# S32M24x register map
Vendor: NXP Semiconductors; File version: 1.5
CPU: CM4 r0p1, little endian, MPU, FPU, VTOR, 4 interrupt priority bits
Registers are 32-bit, read-write, reset 0x0 unless marked. A register's access mark holds for its fields unless they carry their own. Offsets are from the block's base; [hi:lo] are bit positions; 'fields as' and 'values as' point back to an identical list.

## HVI_AE — HVM
Base 0x00000200
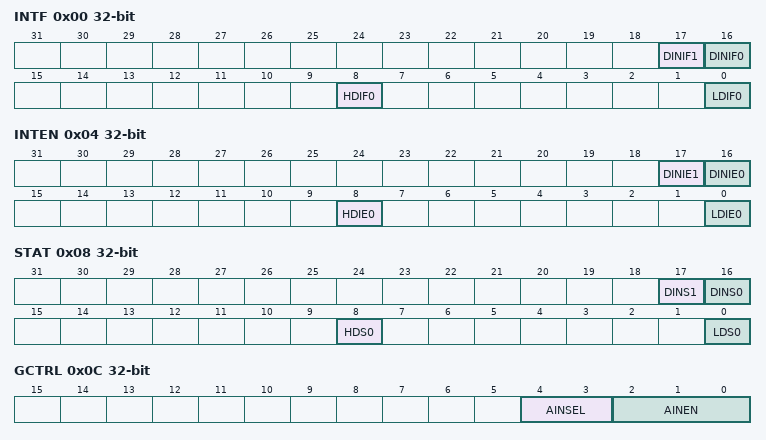
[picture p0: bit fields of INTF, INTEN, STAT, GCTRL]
0x00 INTF write-1-clears — Interrupt Flags
  [17] DINIF1 write-1-clears — Digital Input Interrupt Flag 1
    0=NO_DINIF (HVI n did not detect an event on its digital input.); 1=ACTIVE_DINIF (HVI n detected an event on its digital input.)
  [16] DINIF0 write-1-clears — Digital Input Interrupt Flag 0
    values as DINIF1
  [8] HDIF0 write-1-clears — High Detect Interrupt Flag 0
    0=NO_HVDBATS (VM n did not detect a high voltage since the last clearing of the bit.); 1=ACTIVE_HVDBATS (VM n detected a high voltage since the last clearing of the bit.)
  [0] LDIF0 write-1-clears — Low Detect Interrupt Flag 0
    0=NO_LVD (VM n did not detect a low voltage since the last clearing of the bit.); 1=ACTIVE_LVD (VM n detected a low voltage since the last clearing of this bit.)
0x04 INTEN — Interrupt Enables
  [all] fields
    0=disint (Disable interrupt); 1=enint (Enable interrupt)
  [17] DINIE1 — Digital Input Interrupt Enable 1
  [16] DINIE0 — Digital Input Interrupt Enable 0
  [8] HDIE0 — High Detect Interrupt Enable 0
  [0] LDIE0 — Low Detect Interrupt Enable 0
0x08 STAT ro — Status
  [17] DINS1 — Digital Input Status 1
    0=ZERO (The digital input is in the inactive state with respect to the defined polarity.); 1=ONE (The digital input is in the active state with respect to the defined polarity.)
  [16] DINS0 — Digital Input Status 0
    values as DINS1
  [8] HDS0 — High Detect Status 0
    0=ZERO (The high voltage monitor does not detect a voltage above the upper limit.); 1=ONE (The high voltage monitor does detect a voltage above the upper limit.)
  [0] LDS0 — Low Detect Status 0
    0=ZERO (The low voltage monitor does not detect a voltage below the lower limit.); 1=ONE (The low voltage monitor does detect a voltage below the lower limit.)
0x0C GCTRL — Global Control
  [4:3] AINSEL — Analog Input Selection
    0=ZERO (The analog output is high ohmic.); 1=ONE (The buffered input is the analog output signal.); 2=TWO (The down-divided, buffered high voltage input is the analog output signal.); 3=three (The unbuffered input is the analog output signal.)
  [2:0] AINEN — Analog Input Enable
    0=ZERO (HVI0 is driving the analog output.); 1=ONE (HVI1 is driving the analog output.)
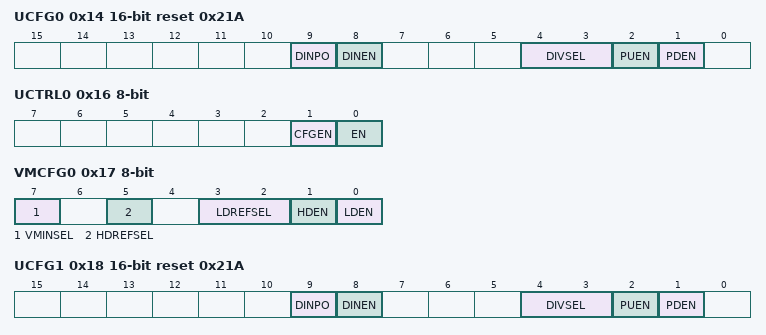
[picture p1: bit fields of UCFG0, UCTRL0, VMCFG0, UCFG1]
0x14 UCFG0 16-bit reset 0x21A — Unit Configuration 0
  [9] DINPO — Digital Input Polarity
    0=falling_edge (An event is created when the digital input is logic low.); 1=rising_edge (An event is created when the digital input is logic high)
  [8] DINEN — Digital Input Enable
    0=din_disabled (Disable the digital input); 1=din_enabled (Enable the digital input)
  [4:3] DIVSEL — Divider Select
    0=div_by_2 (Divide input voltage by 2); 1=div_by_6 (Divide input voltage by 6); 2=div_by_11 (Divide input voltage by 11); 3=div_by_16 (Divide input voltage by 16)
  [2] PUEN — Pull Up Enable
    0=pu_disabled (Disable pull up); 1=pu_enabled (Enable pull up)
  [1] PDEN — Pull Down Enable
    0=pd_disabled (Disable pull down. Voltage Division = 1); 1=pd_enabled (Enable pull down)
0x16 UCTRL0 8-bit — Unit Control 0
  [1] CFGEN — Configuration Enable
    0=disabled (instance 0 is out of configuration mode); 1=enabled (instance 0 is in configuration mode)
  [0] EN — Enable
    0=Disabled. All features of HVI0 are turned-off.; 1=Enabled. All features of HVI0 are used as configured.
0x17 VMCFG0 8-bit — Voltage Monitor Configuration 0
  [7] VMINSEL — Voltage Monitor Input Select
    0=internal (The high voltage input, divided down by the voltage divider, is monitored.); 1=external (The sense voltage is monitored.)
  [5] HDREFSEL — High Detect Reference Select
    0=lowest_voltage_level_hd (Select the lowest reference voltage level (see "HBI 1" in the datasheet)); 1=highest_voltage_level_hd (Select the highest reference voltage level (see "HBI 2" in the datasheet))
  [3:2] LDREFSEL — Low Detect Reference Voltage Select
    0=lowest_level_ld (select the lowest reference voltage level (see "LBI 1" in the datasheet)); 1=second_lowest_level_ld (select the second lowest reference voltage level (see "LBI 2" in the datasheet)); 2=second_highest_level_ld (select the second highest reference voltage level (see "LBI 3" in the datasheet)); 3=highest_level_ld (select the highest reference voltage level (see "LBI 4" in the datasheet))
  [1] HDEN — High Detect Enable
    0=ibe_high_disable (Turn off the high voltage detect comparator); 1=ibe_high_enable (Enable the high voltage detect comparator)
  [0] LDEN — Low Detect Enable
    0=ibe_low_disable (Turn off the low voltage detection); 1=ibe_low_enable (Enable the low voltage detection)
0x18 UCFG1 16-bit reset 0x21A — Unit Configuration 1
  fields as UCFG0
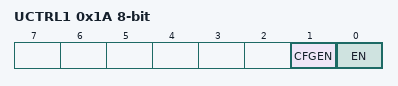
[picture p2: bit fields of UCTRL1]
0x1A UCTRL1 8-bit — Unit Control 1
  [1] CFGEN — Configuration Enable
    0=disabled (instance 1 is out of configuration mode); 1=enabled (instance 1 is in configuration mode)
  [0] EN — Enable
    0=Disabled. All features of HVI1 are turned-off.; 1=Enabled. All features of HVI1 are used as configured.
